# NUC100DN_v1 register map
File version: 1.0
Registers are 32-bit, read-write, reset 0x0 unless marked. A register's access mark holds for its fields unless they carry their own. Offsets are from the block's base; [hi:lo] are bit positions.

## WDT — WDT Register Map
Base 0x40004000
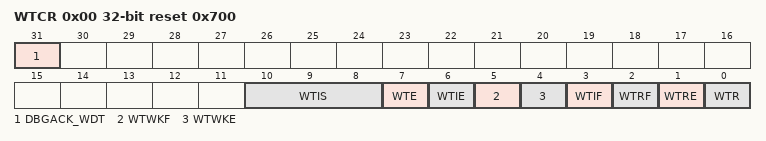
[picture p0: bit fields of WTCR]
0x00 WTCR reset 0x700 — Watchdog Timer Control Register
  [31] DBGACK_WDT — ICE Debug Mode Acknowledge Disable Bit (Write Protect). Watchdog Timer counter will keep going no matter CPU is held by ICE or not.
    0=ICE debug mode acknowledgement effects Watchdog Timer counting; 1=ICE debug mode acknowledgement Disabled
  [10:8] WTIS — Watchdog Timer Interval Selection (Write Protect). These three bits select the time-out interval period for the Watchdog Timer.
    0=24 * WDT_CLK; 1=26 * WDT_CLK; 2=28 * WDT_CLK; 3=210 * WDT_CLK; 4=212 * WDT_CLK; 5=214 * WDT_CLK; 6=216 * WDT_CLK; 7=218 * WDT_CLK
  [7] WTE — Watchdog Timer Enable Bit (Write Protect). Note: If CWDTEN (Config0[31] watchdog enable) bit is set to 0, this bit is forced as 1 and software cannot change this bit to 0.
    0=Watchdog Timer Disabled (This action will reset the internal counter); 1=Watchdog Timer Enabled
  [6] WTIE — Watchdog Timer Interrupt Enable Bit (Write Protect). If this bit is enabled, the WDT time-out interrupt signal is generated and inform to CPU.
    0=Watchdog Timer interrupt Disabled; 1=Watchdog Timer interrupt Enabled
  [5] WTWKF — Watchdog Timer Wake-up Flag. This bit indicates the interrupt wake-up flag status of WDT. Note: This bit is cleared by writing 1 to this bit..
    0=Watchdog Timer does not cause chip wake-up; 1=Chip wake-up from Idle or Power-down mode if WDT time-out interrupt signal generated
  [4] WTWKE — Watchdog Timer Wake-up Function Enable Bit (Write Protect). If this bit is set to 1, while WDT interrupt flag (WTCR[3] WTIF) is generated to 1 and WTIE (WTCR[6] WDT interrupt enable) is enabled, the WDT time-out interrupt signal will generate a wake-up trigger event to chip. Note: Chip can be woken-up by WDT time-out interrupt signal generated only if WDT clock source is selected to 10 kHz oscillator.
    0=Wake-up trigger event Disabled if WDT time-out interrupt signal generated; 1=Wake-up trigger event Enabled if WDT time-out interrupt signal generated
  [3] WTIF — Watchdog Timer Interrupt Flag. This bit will set to 1 while WDT counter value reaches the selected WDT time-out interval. Note: This bit is cleared by writing 1 to this bit.
    0=Watchdog Timer time-out interrupt did not occur; 1=Watchdog Timer time-out interrupt occurred
  [2] WTRF — Watchdog Timer Reset Flag. This bit indicates the system has been reset by WDT time-out reset or not. Note: This bit is cleared by writing 1 to this bit.
    0=Watchdog Timer time-out reset did not occur; 1=Watchdog Timer time-out reset occurred
  [1] WTRE — Watchdog Timer Reset Enable Bit (Write Protect). Setting this bit will enable the Watchdog Timer time-out reset function if the WDT counter value has not been cleared after the specific WDT reset delay period expires.
    0=Watchdog Timer time-out reset function Disabled; 1=Watchdog Timer time-out reset function Enabled
  [0] WTR — Reset Watchdog Timer Counter (Write Protect). Note: This bit will be automatically cleared by hardware.
    0=No effect; 1=Reset the internal 18-bit WDT counter
0x04 WTCRALT — Watchdog Timer Alternative Control Register
  [1:0] WTRDSEL — Watchdog Timer Reset Delay Select (Write Protect). When WDT time-out happened, software has a time named WDT reset delay period to clear WDT counter to prevent WDT time-out reset happened. Software can select a suitable value of WDT reset delay period for different WDT time-out period. These bits are protected bit. It means programming this bit needs to write "59h", "16h", "88h" to address 0x5000_0100 to disable register protection. Reference the register REGWRPROT at address GCR_BA+0x100. This register will be reset to 0 if WDT time-out reset happened
    0=Watchdog Timer reset delay period is (1024+2) * WDT_CLK; 1=Watchdog Timer reset delay period is (128+2) * WDT_CLK; 2=Watchdog Timer reset delay period is (16+2) * WDT_CLK; 3=Watchdog Timer reset delay period is (1+2) * WDT_CLK
